# CH32V407 register map
Vendor: WCH Ltd.; File version: 1.0
Registers are 32-bit, read-write, reset 0x0 unless marked. A register's access mark holds for its fields unless they carry their own. Offsets are from the block's base; [hi:lo] are bit positions; {n}, {i} and the like mark numbered series.

## PWR — Power control
Base 0x40007000
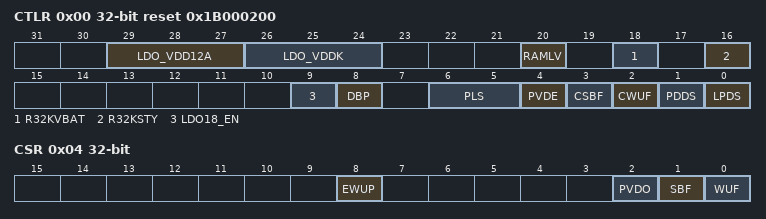
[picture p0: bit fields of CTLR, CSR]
0x00 CTLR reset 0x1B000200 — Power control register (PWR_CTRL)
  [29:27] LDO_VDD12A — VDD12A voltage regulation position
  [26:24] LDO_VDDK — VDDK voltage regulation position
  [20] RAMLV — Ram LV Enable
  [18] R32KVBAT — VBAT 32k ram enable
  [16] R32KSTY — standby 32k ram enable
  [9] LDO18_EN — VDD18 enable
  [8] DBP — Disable Backup Domain write protection
  [6:5] PLS — PVD Level Selection
  [4] PVDE — Power Voltage Detector Enable
  [3] CSBF — Clear STANDBY Flag
  [2] CWUF — Clear Wake-up Flag
  [1] PDDS — Power Down Deep Sleep
  [0] LPDS — Low Power Deep Sleep
0x04 CSR access per field — Power control register (PWR_CSR)
  [8] EWUP rw — Enable WKUP pin
  [2] PVDO ro — PVD Output
  [1] SBF ro — STANDBY Flag
  [0] WUF ro — Wake-Up Flag

## BKP — Backup registers
Base 0x40006C00
{0x0+4i} DATAR{i} (i=1..10) — Backup data register (BKP_DR)
  [15:0] D{i} — Backup data
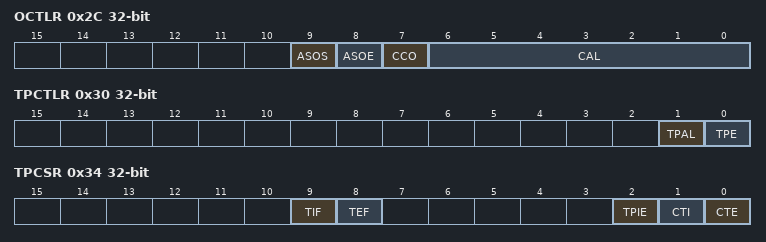
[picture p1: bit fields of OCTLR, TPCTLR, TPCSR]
0x2C OCTLR — RTC clock calibration register (BKP_OCTLR)
  [9] ASOS — Alarm or second output selection
  [8] ASOE — Alarm or second output enable
  [7] CCO — Calibration Clock Output
  [6:0] CAL — Calibration value
0x30 TPCTLR — Backup control register (BKP_TPCTLR)
  [1] TPAL — Tamper pin active level
  [0] TPE — Tamper pin enable
0x34 TPCSR access per field — BKP_TPCSR control/status register (BKP_CSR)
  [9] TIF ro — Tamper Interrupt Flag
  [8] TEF ro — Tamper Event Flag
  [2] TPIE rw — Tamper Pin interrupt enable
  [1] CTI wo — Clear Tamper Interrupt
  [0] CTE wo — Clear Tamper event
{0x14+4i} DATAR{i} (i=11..13) — Backup data register (BKP_DR)
  [15:0] DR{i} — Backup data
{0x14+4i} DATAR{i} (i=14..42) — Backup data register (BKP_DR)
  [15:0] D{i} — Backup data

## CRC — CRC calculation unit
Base 0x40023000
0x00 DATAR reset 0xFFFFFFFF — Data register
  [31:0] DR — Data Register
0x04 IDATAR 8-bit — Independent Data register
  [7:0] IDR
0x08 CTLR wo — Control register
  [0] RESET — Reset bit

## RTC — Real time clock
Base 0x40002800
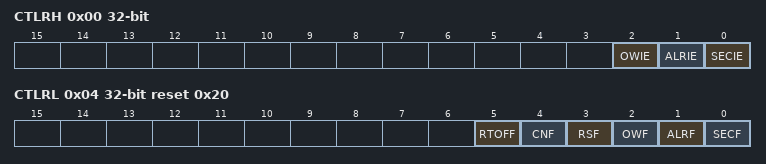
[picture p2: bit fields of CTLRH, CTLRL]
0x00 CTLRH — RTC Control Register High
  [2] OWIE — Overflow interrupt Enable
  [1] ALRIE — Alarm interrupt Enable
  [0] SECIE — Second interrupt Enable
0x04 CTLRL access per field reset 0x20 — RTC Control Register Low
  [5] RTOFF ro — RTC operation OFF
  [4] CNF rw — Configuration Flag
  [3] RSF rw — Registers Synchronized Flag
  [2] OWF rw — Overflow Flag
  [1] ALRF rw — Alarm Flag
  [0] SECF rw — Second Flag
0x08 PSCRH wo — RTC Prescaler Load Register High
  [3:0] PRL
0x0C PSCRL wo reset 0x8000 — RTC Prescaler Load Register Low
  [15:0] PRL — RTC Prescaler Divider Register Low
0x10 DIVH ro — RTC Prescaler Divider Register High
  [3:0] DIV — RTC prescaler divider register high
0x14 DIVL ro reset 0x8000 — RTC Prescaler Divider Register Low
  [15:0] DIV — RTC prescaler divider register Low
0x18 CNTH — RTC Counter Register High
  [15:0] CNT — RTC counter register high
0x1C CNTL — RTC Counter Register Low
  [15:0] CNT — RTC counter register Low
0x20 ALRMH wo reset 0xFFFF — RTC Alarm Register High
  [15:0] ALR — RTC alarm register high
0x24 ALRML wo reset 0xFFFF — RTC Alarm Register Low
  [15:0] ALR — RTC alarm register low

## IWDG — Independent watchdog
Base 0x40003000
0x00 CTLR wo — Key register (IWDG_CTLR)
  [15:0] KEY — Key value
0x04 PSCR — Prescaler register (IWDG_PSCR)
  [2:0] PR — Prescaler divider
0x08 RLDR reset 0xFFF — Reload register (IWDG_RLDR)
  [11:0] RL — Watchdog counter reload value
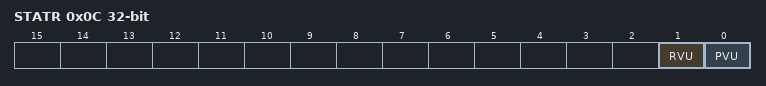
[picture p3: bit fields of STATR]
0x0C STATR ro — Status register (IWDG_SR)
  [1] RVU — Watchdog counter reload value update
  [0] PVU — Watchdog prescaler value update

## WWDG — Window watchdog
Base 0x40002C00
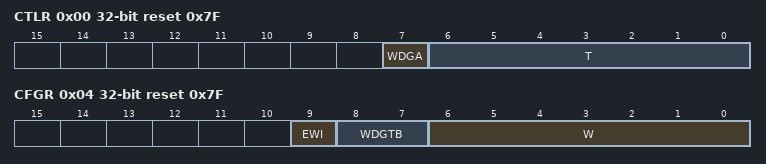
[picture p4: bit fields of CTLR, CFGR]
0x00 CTLR reset 0x7F — Control register (WWDG_CR)
  [7] WDGA — Activation bit
  [6:0] T — 7-bit counter (MSB to LSB)
0x04 CFGR reset 0x7F — Configuration register (WWDG_CFGR)
  [9] EWI — Early Wakeup Interrupt
  [8:7] WDGTB — Timer Base
  [6:0] W — 7-bit window value
0x08 STATR — Status register (WWDG_SR)
  [0] EWIF — Early Wakeup Interrupt Flag
